# VPAC1_COMMON_0_PAR_VPAC_LDC0_S_VBUSP_VPAC_LDC_LSE_CFG_VP register map
Vendor: Texas Instruments
Peripheral module from a debugger description file (folder J7_AHP).
Registers are 32-bit, read-only, reset values left out (the file's numbers can be read two ways) unless marked. A register's access mark holds for its fields unless they carry their own. Offsets are as the file gives them; lines under a group give offsets from that group; [hi:lo] are bit positions; {n}, {i} and the like mark numbered series; 'fields as' and 'values as' point back to an identical list; <NAME> marks a mode.

## VPAC1_COMMON_0_PAR_VPAC_LDC0_S_VBUSP_VPAC_LDC_LSE_CFG_VP
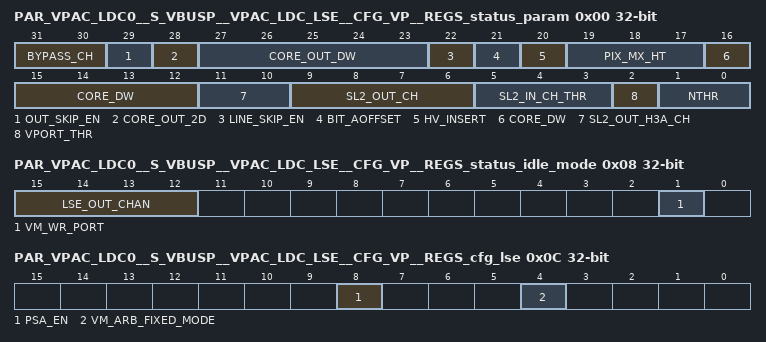
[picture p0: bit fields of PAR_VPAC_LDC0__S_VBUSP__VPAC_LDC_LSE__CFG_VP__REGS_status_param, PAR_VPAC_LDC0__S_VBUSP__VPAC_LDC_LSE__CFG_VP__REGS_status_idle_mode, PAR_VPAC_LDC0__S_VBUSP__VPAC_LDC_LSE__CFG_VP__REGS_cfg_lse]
0x00 PAR_VPAC_LDC0__S_VBUSP__VPAC_LDC_LSE__CFG_VP__REGS_status_param
  [31:30] BYPASS_CH — Number of available input channel selection for loopback mode
  [29] OUT_SKIP_EN — Output Auto-Skip Enable
  [28] CORE_OUT_2D — 1D or 2D output addressing mode(2D if 1)
  [27:23] CORE_OUT_DW — Core Output Channel Data Width
  [22] LINE_SKIP_EN — Source Line Inc by 2 Supported (if 1)
  [21] BIT_AOFFSET — Source nibble offset address Supported (if 1)
  [20] HV_INSERT — H/VBLANK Insertion Supported (if 1)
  [19:17] PIX_MX_HT — Core_Input Pixel Matrix Height
  [16:12] CORE_DW — Core Input Data Bus Width
  [11:10] SL2_OUT_H3A_CH — Number of SL2 H3A Output Channels
  [9:6] SL2_OUT_CH — Number of SL2 Output Channels
  [5:3] SL2_IN_CH_THR — Number of Input Channels per thread
  [2] VPORT_THR — Number of VPORT input enabled
  [1:0] NTHR — Number of threads supported
0x04 PAR_VPAC_LDC0__S_VBUSP__VPAC_LDC_LSE__CFG_VP__REGS_status_error access not given
  [14:8] VM_WR_ERR — VBUSM I/F Last Write Error Status [14:11] Write Channel Number [10:8] VBUSM write error status (access R/W1TC)
0x08 PAR_VPAC_LDC0__S_VBUSP__VPAC_LDC_LSE__CFG_VP__REGS_status_idle_mode
  [15:12] LSE_OUT_CHAN — Output Channel[3:0] Status
  [1] VM_WR_PORT — SL2 vbusm I/F Write Port Status
0x0C PAR_VPAC_LDC0__S_VBUSP__VPAC_LDC_LSE__CFG_VP__REGS_cfg_lse rw
  [8] PSA_EN — Test mode Output Channel Signature Generation Enable 0: Disable (default) 1: Enable When enabled, LSE generates a unique CRC signature for each output channel's frame data at frame completion.
  [4] VM_ARB_FIXED_MODE — VBUSM Arbitration Fixed Mode select 0: Round-Robin Arbitration (default) 1: Fixed-mode Arbitration
0x13C PAR_VPAC_LDC0__S_VBUSP__VPAC_LDC_LSE__CFG_VP__REGS_dst_common_cfg rw
  [5:0] ROUNDING_OFFSET — output channel rounding offset value. Default value to be considered 6'h08
0x140 PAR_VPAC_LDC0__S_VBUSP__VPAC_LDC_LSE__CFG_VP__REGS_psa_signature
  [31:0] VALUE — 32-bit CRC signature value
0x1E0 PAR_VPAC_LDC0__S_VBUSP__VPAC_LDC_LSE__CFG_VP__REGS_dbg
  [31:0] STATUS — Debug status
